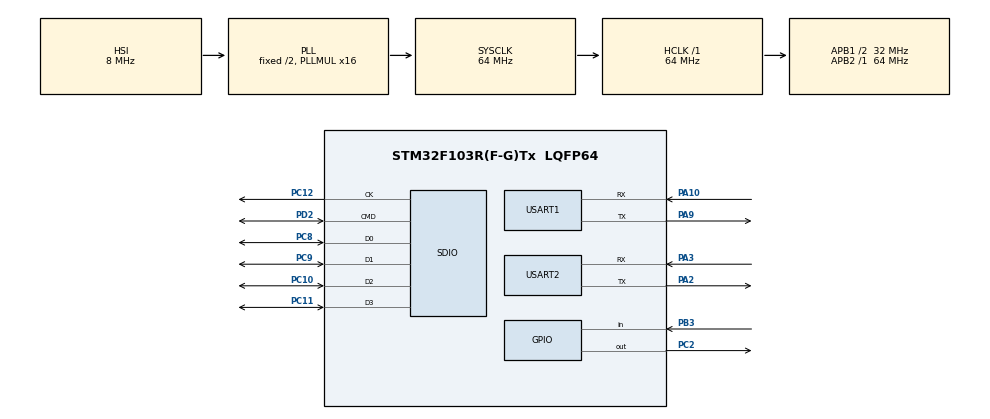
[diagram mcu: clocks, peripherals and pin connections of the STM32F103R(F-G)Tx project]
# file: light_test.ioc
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Dma.Request0=SDIO
Dma.SDIO.0.Direction=DMA_MEMORY_TO_PERIPH
Dma.SDIO.0.Instance=DMA2_Channel4
Dma.SDIO.0.MemDataAlignment=DMA_MDATAALIGN_WORD
Dma.SDIO.0.MemInc=DMA_MINC_ENABLE
Dma.SDIO.0.Mode=DMA_NORMAL
Dma.SDIO.0.PeriphDataAlignment=DMA_PDATAALIGN_WORD
Dma.SDIO.0.PeriphInc=DMA_PINC_DISABLE
Dma.SDIO.0.Priority=DMA_PRIORITY_LOW
FATFS.BSP.number=1
FATFS._CODE_PAGE=936
FATFS._USE_LFN=0
FATFS0.BSP.STBoard=false
FATFS0.BSP.api=Unknown
FATFS0.BSP.instance=PB3
FATFS0.BSP.ip=GPIO
FATFS0.BSP.mode=Input
FATFS0.BSP.name=Detect_SDIO
FATFS0.BSP.solution=PB3
FREERTOS.Mutexes01=printMutex,Dynamic,NULL,Depleted;rtcMutex,Dynamic,NULL,Available
FREERTOS.Queues01=sdCmdQueue,5,uint32_t,0,Dynamic,NULL,NULL
FREERTOS.Tasks01=defaultTask,0,128,StartDefaultTask,Default,NULL,Dynamic,NULL,NULL;cmdTask,2,256,CMDTask,As external,NULL,Dynamic,NULL,NULL;sdTask,0,1024,SDTask,As external,NULL,Dynamic,NULL,NULL;testTask,2,256,TestTask,As external,NULL,Dynamic,NULL,NULL
FREERTOS.configTOTAL_HEAP_SIZE=15360
IWDG.Prescaler=IWDG_PRESCALER_32
Mcu.Family=STM32F1
Mcu.Name=STM32F103R(F-G)Tx
Mcu.Package=LQFP64
NVIC.DMA2_Channel4_5_IRQn=true\:6\:0\:true\:false\:true\:true\:false\:true\:true
NVIC.PriorityGroup=NVIC_PRIORITYGROUP_4
NVIC.RTC_IRQn=true\:5\:0\:false\:false\:true\:true\:true\:true\:true
NVIC.SDIO_IRQn=true\:5\:0\:false\:false\:true\:true\:true\:true\:true
NVIC.TIM7_IRQn=true\:15\:0\:false\:false\:true\:false\:false\:true\:true
NVIC.TimeBase=TIM7_IRQn
NVIC.TimeBaseIP=TIM7
NVIC.USART1_IRQn=true\:5\:0\:false\:false\:true\:true\:true\:true\:true
NVIC.USART2_IRQn=true\:5\:0\:false\:false\:true\:true\:true\:true\:true
PA10.Mode=Asynchronous
PA10.Signal=USART1_RX
PA13.Mode=Serial_Wire
PA13.Signal=SYS_JTMS-SWDIO
PA14.Mode=Serial_Wire
PA14.Signal=SYS_JTCK-SWCLK
PA2.Mode=Asynchronous
PA2.Signal=USART2_TX
PA3.Mode=Asynchronous
PA3.Signal=USART2_RX
PA9.Mode=Asynchronous
PA9.Signal=USART1_TX
PB3.Signal=GPIO_Input
PC10.Mode=SD_4_bits_Wide_bus
PC10.Signal=SDIO_D2
PC11.Mode=SD_4_bits_Wide_bus
PC11.Signal=SDIO_D3
PC12.Mode=SD_4_bits_Wide_bus
PC12.Signal=SDIO_CK
PC14-OSC32_IN.Mode=LSE-External-Oscillator
PC14-OSC32_IN.Signal=RCC_OSC32_IN
PC15-OSC32_OUT.Mode=LSE-External-Oscillator
PC15-OSC32_OUT.Signal=RCC_OSC32_OUT
PC2.Signal=GPIO_Output
PC8.Mode=SD_4_bits_Wide_bus
PC8.Signal=SDIO_D0
PC9.Mode=SD_4_bits_Wide_bus
PC9.Signal=SDIO_D1
PD2.Mode=SD_4_bits_Wide_bus
PD2.Signal=SDIO_CMD
ProjectManager.HeapSize=0x4000
ProjectManager.StackSize=0x4000
ProjectManager.TargetToolchain=MDK-ARM V5.32
RCC.AHBFreq_Value=64000000
RCC.APB1CLKDivider=RCC_HCLK_DIV2
RCC.APB1Freq_Value=32000000
RCC.APB1TimFreq_Value=64000000
RCC.APB2Freq_Value=64000000
RCC.APB2TimFreq_Value=64000000
RCC.HCLKFreq_Value=64000000
RCC.PLLMUL=RCC_PLL_MUL16
RCC.RTCClockSelection=RCC_RTCCLKSOURCE_LSE
RCC.SYSCLKFreq_VALUE=64000000
RCC.SYSCLKSource=RCC_SYSCLKSOURCE_PLLCLK
RCC.USBFreq_Value=64000000
RTC.AutoPrediv=RTC_AUTO_1_SECOND
SDIO.ClockDiv=16
USART1.VirtualMode=VM_ASYNC
USART2.VirtualMode=VM_ASYNC
VP_FATFS_VS_SDIO.Mode=SDIO
VP_FREERTOS_VS_CMSIS_V1.Mode=CMSIS_V1
VP_IWDG_VS_IWDG.Mode=IWDG_Activate
VP_RTC_No_RTC_Output.Mode=RTC_OUT_NO
VP_RTC_VS_RTC_Activate.Mode=RTC_Enabled
VP_RTC_VS_RTC_Calendar.Mode=RTC_Calendar
VP_SYS_VS_tim7.Mode=TIM7
board=custom

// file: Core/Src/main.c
/* USER CODE BEGIN Header */
/**
  ******************************************************************************
  * @file           : main.c
  * @brief          : Main program body
  ******************************************************************************
  * @attention
  *
  * Copyright (c) 2025 STMicroelectronics.
  * All rights reserved.
  *
  * This software is licensed under terms that can be found in the LICENSE file
  * in the root directory of this software component.
  * If no LICENSE file comes with this software, it is provided AS-IS.
  *
  ******************************************************************************
  */
/* USER CODE END Header */
#include "main.h"
#include "cmsis_os.h"
#include "dma.h"
#include "fatfs.h"
#include "iwdg.h"
#include "rtc.h"
#include "sdio.h"
#include "usart.h"
#include "gpio.h"

/* USER CODE BEGIN PTD */
uint8_t rx1Mutex = 0;  // Mutexes for UART receive buffers， 0：not locked, 1: locked
uint8_t rx2Mutex = 0;  // Mutexes for UART receive buffers， 0：not locked, 1: locked
uint8_t debugMode = 0; // 0: normal, 1: debug
/* USER CODE END PTD */

void SystemClock_Config(void);
void MX_FREERTOS_Init(void);

int main(void)
{

  /* MCU Configuration--------------------------------------------------------*/

  /* Reset of all peripherals, Initializes the Flash interface and the Systick. */
  HAL_Init();

  /* Configure the system clock */
  SystemClock_Config();

  /* Initialize all configured peripherals */
  MX_IWDG_Init();
  MX_GPIO_Init();
  MX_DMA_Init();
  MX_RTC_Init();
  MX_SDIO_SD_Init();
  MX_USART1_UART_Init();
  MX_USART2_UART_Init();
  MX_FATFS_Init();

  /* Call init function for freertos objects (in cmsis_os2.c) */
  MX_FREERTOS_Init();

  /* Start scheduler */
  osKernelStart();

  /* We should never get here as control is now taken by the scheduler */

  /* Infinite loop */
  while (1)
  {

  }
}

void SystemClock_Config(void)
{
  RCC_OscInitTypeDef RCC_OscInitStruct = {0};
  RCC_ClkInitTypeDef RCC_ClkInitStruct = {0};
  RCC_PeriphCLKInitTypeDef PeriphClkInit = {0};

  /** Initializes the RCC Oscillators according to the specified parameters
  * in the RCC_OscInitTypeDef structure.
  */
  RCC_OscInitStruct.OscillatorType = RCC_OSCILLATORTYPE_HSI|RCC_OSCILLATORTYPE_LSI
                              |RCC_OSCILLATORTYPE_LSE;
  RCC_OscInitStruct.LSEState = RCC_LSE_ON;
  RCC_OscInitStruct.HSIState = RCC_HSI_ON;
  RCC_OscInitStruct.HSICalibrationValue = RCC_HSICALIBRATION_DEFAULT;
  RCC_OscInitStruct.LSIState = RCC_LSI_ON;
  RCC_OscInitStruct.PLL.PLLState = RCC_PLL_ON;
  RCC_OscInitStruct.PLL.PLLSource = RCC_PLLSOURCE_HSI_DIV2;
  RCC_OscInitStruct.PLL.PLLMUL = RCC_PLL_MUL16;
  if (HAL_RCC_OscConfig(&RCC_OscInitStruct) != HAL_OK)
  {
    Error_Handler();
  }

  /** Initializes the CPU, AHB and APB buses clocks
  */
  RCC_ClkInitStruct.ClockType = RCC_CLOCKTYPE_HCLK|RCC_CLOCKTYPE_SYSCLK
                              |RCC_CLOCKTYPE_PCLK1|RCC_CLOCKTYPE_PCLK2;
  RCC_ClkInitStruct.SYSCLKSource = RCC_SYSCLKSOURCE_PLLCLK;
  RCC_ClkInitStruct.AHBCLKDivider = RCC_SYSCLK_DIV1;
  RCC_ClkInitStruct.APB1CLKDivider = RCC_HCLK_DIV2;
  RCC_ClkInitStruct.APB2CLKDivider = RCC_HCLK_DIV1;

  if (HAL_RCC_ClockConfig(&RCC_ClkInitStruct, FLASH_LATENCY_2) != HAL_OK)
  {
    Error_Handler();
  }
  PeriphClkInit.PeriphClockSelection = RCC_PERIPHCLK_RTC;
  PeriphClkInit.RTCClockSelection = RCC_RTCCLKSOURCE_LSE;
  if (HAL_RCCEx_PeriphCLKConfig(&PeriphClkInit) != HAL_OK)
  {
    Error_Handler();
  }
}

void HAL_TIM_PeriodElapsedCallback(TIM_HandleTypeDef *htim)
{
  if (htim->Instance == TIM7) {
    HAL_IncTick();
  }
}

void Error_Handler(void)
{
  __disable_irq();
  while (1)
  {
  }
}

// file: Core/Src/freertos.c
/* USER CODE BEGIN Header */
/**
  ******************************************************************************
  * File Name          : freertos.c
  * Description        : Code for freertos applications
  ******************************************************************************
  * @attention
  *
  * Copyright (c) 2025 STMicroelectronics.
  * All rights reserved.
  *
  * This software is licensed under terms that can be found in the LICENSE file
  * in the root directory of this software component.
  * If no LICENSE file comes with this software, it is provided AS-IS.
  *
  ******************************************************************************
  */
/* USER CODE END Header */

#include "FreeRTOS.h"
#include "task.h"
#include "main.h"
#include "cmsis_os.h"

/* USER CODE BEGIN Includes */
#include "iwdg.h"
#include "SDTask.h"
/* USER CODE END Includes */

/* USER CODE BEGIN Variables */
osPoolId  sdCmdQueuePoolHandle;
/* USER CODE END Variables */
osThreadId defaultTaskHandle;
osThreadId cmdTaskHandle;
osThreadId sdTaskHandle;
osThreadId testTaskHandle;
osMessageQId sdCmdQueueHandle;
osMutexId printMutexHandle;
osMutexId rtcMutexHandle;

void StartDefaultTask(void const * argument);
extern void CMDTask(void const * argument);
extern void SDTask(void const * argument);
extern void TestTask(void const * argument);

void MX_FREERTOS_Init(void); /* (MISRA C 2004 rule 8.1) */

/* GetIdleTaskMemory prototype (linked to static allocation support) */
void vApplicationGetIdleTaskMemory( StaticTask_t **ppxIdleTaskTCBBuffer, StackType_t **ppxIdleTaskStackBuffer, uint32_t *pulIdleTaskStackSize );

/* USER CODE BEGIN GET_IDLE_TASK_MEMORY */
static StaticTask_t xIdleTaskTCBBuffer;
static StackType_t xIdleStack[configMINIMAL_STACK_SIZE];

void vApplicationGetIdleTaskMemory( StaticTask_t **ppxIdleTaskTCBBuffer, StackType_t **ppxIdleTaskStackBuffer, uint32_t *pulIdleTaskStackSize )
{
  *ppxIdleTaskTCBBuffer = &xIdleTaskTCBBuffer;
  *ppxIdleTaskStackBuffer = &xIdleStack[0];
  *pulIdleTaskStackSize = configMINIMAL_STACK_SIZE;
  /* place for user code */
}
/* USER CODE END GET_IDLE_TASK_MEMORY */

void MX_FREERTOS_Init(void) {
  /* Create the mutex(es) */
  /* definition and creation of printMutex */
  osMutexDef(printMutex);
  printMutexHandle = osMutexCreate(osMutex(printMutex));

  /* definition and creation of rtcMutex */
  osMutexDef(rtcMutex);
  rtcMutexHandle = osMutexCreate(osMutex(rtcMutex));

  /* Create the queue(s) */
  /* definition and creation of sdCmdQueue */
  osMessageQDef(sdCmdQueue, 5, uint32_t);
  sdCmdQueueHandle = osMessageCreate(osMessageQ(sdCmdQueue), NULL);

  /* USER CODE BEGIN RTOS_QUEUES */
  /* add queues, ... */
  osPoolDef(sdCmdQueuePool, 5, sdStruct);
  sdCmdQueuePoolHandle = osPoolCreate(osPool(sdCmdQueuePool));
  /* USER CODE END RTOS_QUEUES */

  /* Create the thread(s) */
  /* definition and creation of defaultTask */
  osThreadDef(defaultTask, StartDefaultTask, osPriorityNormal, 0, 128);
  defaultTaskHandle = osThreadCreate(osThread(defaultTask), NULL);

  /* definition and creation of cmdTask */
  osThreadDef(cmdTask, CMDTask, osPriorityHigh, 0, 256);
  cmdTaskHandle = osThreadCreate(osThread(cmdTask), NULL);

  /* definition and creation of sdTask */
  osThreadDef(sdTask, SDTask, osPriorityNormal, 0, 1024);
  sdTaskHandle = osThreadCreate(osThread(sdTask), NULL);

  /* definition and creation of testTask */
  osThreadDef(testTask, TestTask, osPriorityHigh, 0, 256);
  testTaskHandle = osThreadCreate(osThread(testTask), NULL);

}

void StartDefaultTask(void const * argument)
{
  /* USER CODE BEGIN StartDefaultTask */
  /* Infinite loop */
  for(;;)
  {
    osDelay(500);
    HAL_IWDG_Refresh(&hiwdg);
    HAL_GPIO_TogglePin(GPIOC, GPIO_PIN_2);
  }
  /* USER CODE END StartDefaultTask */
}
